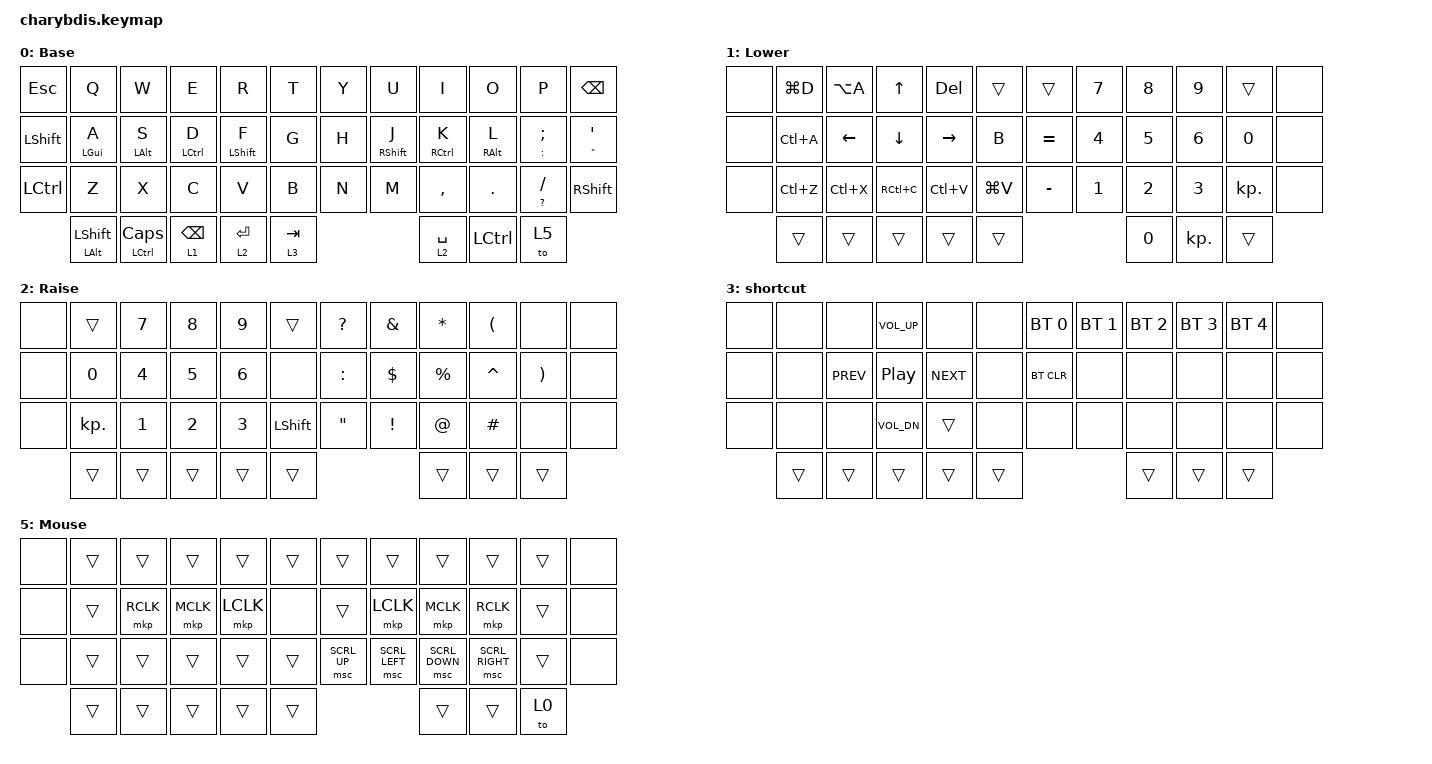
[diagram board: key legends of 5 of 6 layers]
#include <dt-bindings/zmk/mouse.h>
#include <behaviors.dtsi>
#include <dt-bindings/zmk/bt.h>
#include <dt-bindings/zmk/keys.h>
#include <dt-bindings/zmk/pointing.h>

&lt {
    tapping-term-ms = <240>;
    flavor = "balanced";
    quick-tap-ms = <150>;
};

&mt {
    global-quick-tap;
    flavor = "tap-preferred";
    tapping-term-ms = <200>;
};

&sk {
    release-after-ms = <2000>;
    quick-release;
};

/ {
    combos {
        compatible = "zmk,combos";

        combo_esc {
            timeout-ms = <50>;
            key-positions = <0 1>;
            bindings = <&kp ESC>;
        };

        left_bkt {
            bindings = <&kp LEFT_BRACKET>;
            key-positions = <4 5>;
            timeout-ms = <50>;
        };

        right_bkt {
            bindings = <&kp RIGHT_BRACKET>;
            key-positions = <6 7>;
            timeout-ms = <50>;
        };

        left_par {
            bindings = <&kp LEFT_PARENTHESIS>;
            key-positions = <16 17>;
            timeout-ms = <50>;
        };

        right_par {
            bindings = <&kp RIGHT_PARENTHESIS>;
            key-positions = <18 19>;
            timeout-ms = <50>;
        };

        bac {
            bindings = <&kp BACKSLASH>;
            key-positions = <5 6>;
            timeout-ms = <50>;
        };

        pipe {
            bindings = <&kp PIPE>;
            key-positions = <17 18>;
            timeout-ms = <50>;
        };
    };

    behaviors {
        hm: homerow_mods {
            compatible = "zmk,behavior-hold-tap";
            label = "HOMEROW_MODS";
            bindings = <&kp>, <&kp>;

            #binding-cells = <2>;
            tapping-term-ms = <200>;
            quick-tap-ms = <180>;
            flavor = "tap-preferred";
        };

        ltq: ltq {
            compatible = "zmk,behavior-hold-tap";
            label = "LTQ";
            bindings = <&mo>, <&kp>;

            #binding-cells = <2>;
            tapping-term-ms = <200>;
            quick-tap-ms = <180>;
        };

        as: auto_shift {
            compatible = "zmk,behavior-hold-tap";
            label = "AUTO_SHIFT";
            bindings = <&kp>, <&kp>;

            #binding-cells = <2>;
            tapping-term-ms = <135>;
            quick-tap-ms = <0>;
        };
    };

    macros {
        macro1: new_macro {
            compatible = "zmk,behavior-macro";
            #binding-cells = <0>;
            bindings = <&kp RIGHT &kp ENTER>;
            label = "NEW_MACRO";
        };
    };

    keymap {
        compatible = "zmk,keymap";

        Base {
            label = "Base";
            bindings = <
&kp ESC         &kp Q                    &kp W           &kp E               &kp R             &kp T      &kp Y  &kp U              &kp I                &kp O             &kp P                &kp BACKSPACE
&kp LEFT_SHIFT  &hm LEFT_GUI A           &hm LEFT_ALT S  &hm LEFT_CONTROL D  &hm LEFT_SHIFT F  &kp G      &kp H  &hm RIGHT_SHIFT J  &hm RIGHT_CONTROL K  &hm RIGHT_ALT L   &as COLON SEMICOLON  &as DOUBLE_QUOTES SINGLE_QUOTE
&kp LCTRL       &kp Z                    &kp X           &kp C               &kp V             &kp B      &kp N  &kp M              &kp COMMA            &kp DOT           &as QUESTION SLASH   &kp RIGHT_SHIFT
                &mt LEFT_ALT LEFT_SHIFT  &mt LCTRL CAPS  &ltq 1 BSPC         &ltq 2 ENTER      &lt 3 TAB                            &ltq 2 SPACE         &kp LEFT_CONTROL  &to 5
            >;
        };

        Lower {
            label = "Lower";
            bindings = <
&none  &kp LG(D)  &kp LA(A)  &kp UP     &kp DELETE  &trans     &trans     &kp N7  &kp N8  &kp N9      &trans      &none
&none  &kp LC(A)  &kp LEFT   &kp DOWN   &kp RIGHT   &kp B      &kp EQUAL  &kp N4  &kp N5  &kp N6      &kp N0      &none
&none  &kp LC(Z)  &kp LC(X)  &kp RC(C)  &kp LC(V)   &kp LG(V)  &kp MINUS  &kp N1  &kp N2  &kp N3      &kp KP_DOT  &none
       &trans     &trans     &trans     &trans      &trans                        &kp N0  &kp KP_DOT  &trans
            >;
        };

        Raise {
            label = "Raise";
            bindings = <
&none  &trans      &kp N7  &kp N8  &kp N9  &trans          &kp QUESTION       &kp AMPS  &kp ASTERISK  &kp LPAR   &none     &none
&none  &kp N0      &kp N4  &kp N5  &kp N6  &none           &kp COLON          &kp DLLR  &kp PRCNT     &kp CARET  &kp RPAR  &none
&none  &kp KP_DOT  &kp N1  &kp N2  &kp N3  &kp LEFT_SHIFT  &kp DOUBLE_QUOTES  &kp EXCL  &kp AT        &kp HASH   &none     &none
       &trans      &trans  &trans  &trans  &trans                                       &trans        &trans     &trans
            >;
        };

        Shortcut {
            label = "shortcut";
            bindings = <
&none  &none   &none       &kp C_VOL_UP  &none       &none   &bt BT_SEL 0  &bt BT_SEL 1  &bt BT_SEL 2  &bt BT_SEL 3  &bt BT_SEL 4  &none
&none  &none   &kp C_PREV  &kp C_PP      &kp C_NEXT  &none   &bt BT_CLR    &none         &none         &none         &none         &none
&none  &none   &none       &kp C_VOL_DN  &trans      &none   &none         &none         &none         &none         &none         &none
       &trans  &trans      &trans        &trans      &trans                              &trans        &trans        &trans
            >;
        };

        Game {
            label = "Game";
            bindings = <
&none   &trans  &trans  &trans  &to 0   &trans  &trans  &trans  &trans  &trans  &none  &none
&trans  &trans  &trans  &trans  &trans  &none   &none   &none   &none   &none   &none  &none
&none   &none   &none   &none   &none   &none   &none   &none   &none   &none   &none  &none
        &none   &none   &none   &none   &none                   &none   &none
            >;
        };

        Mouse {
            bindings = <
&none  &trans  &trans     &trans     &trans     &trans  &trans        &trans          &trans          &trans           &trans  &none
&none  &trans  &mkp RCLK  &mkp MCLK  &mkp LCLK  &none   &trans        &mkp LCLK       &mkp MCLK       &mkp RCLK        &trans  &none
&none  &trans  &trans     &trans     &trans     &trans  &msc SCRL_UP  &msc SCRL_LEFT  &msc SCRL_DOWN  &msc SCRL_RIGHT  &trans  &none
       &trans  &trans     &trans     &trans     &trans                                &trans          &trans           &to 0
            >;
        };
    };
};
